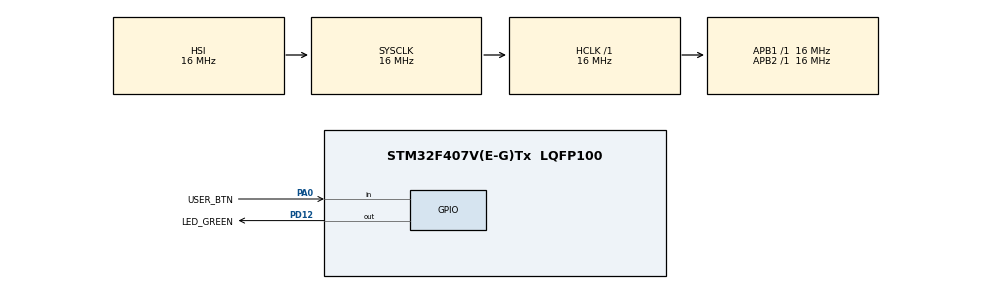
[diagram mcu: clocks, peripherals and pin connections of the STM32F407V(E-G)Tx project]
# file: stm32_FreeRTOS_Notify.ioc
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FREERTOS.Tasks01=LEDTask,25,500,StartLEDTask,Default,NULL,Dynamic,NULL,NULL;BTNTask,25,500,StartBTNTask,Default,NULL,Dynamic,NULL,NULL
FREERTOS.configUSE_NEWLIB_REENTRANT=1
Mcu.Family=STM32F4
Mcu.Name=STM32F407V(E-G)Tx
Mcu.Package=LQFP100
NVIC.PriorityGroup=NVIC_PRIORITYGROUP_4
NVIC.TIM6_DAC_IRQn=true\:15\:0\:false\:false\:true\:false\:false\:true\:true
NVIC.TimeBase=TIM6_DAC_IRQn
NVIC.TimeBaseIP=TIM6
PA0-WKUP.GPIO_Label=USER_BTN
PA0-WKUP.Signal=GPIO_Input
PD12.GPIO_Label=LED_GREEN
PD12.Signal=GPIO_Output
ProjectManager.HeapSize=0x200
ProjectManager.StackSize=0x400
ProjectManager.TargetToolchain=STM32CubeIDE
RCC.AHBFreq_Value=16000000
RCC.APB1Freq_Value=16000000
RCC.APB2Freq_Value=16000000
RCC.CortexFreq_Value=16000000
RCC.HSE_VALUE=25000000
RCC.HSI_VALUE=16000000
RCC.LSE_VALUE=32768
RCC.SYSCLKFreq_VALUE=16000000
RCC.VCOOutputFreq_Value=192000000
VP_FREERTOS_VS_CMSIS_V2.Mode=CMSIS_V2
VP_SYS_VS_tim6.Mode=TIM6
board=custom

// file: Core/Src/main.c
/* USER CODE BEGIN Header */
/**
  ******************************************************************************
  * @file           : main.c
  * @brief          : Main program body
  ******************************************************************************
  * @attention
  *
  * Copyright (c) 2022 STMicroelectronics.
  * All rights reserved.
  *
  * This software is licensed under terms that can be found in the LICENSE file
  * in the root directory of this software component.
  * If no LICENSE file comes with this software, it is provided AS-IS.
  *
  ******************************************************************************
  */
/* USER CODE END Header */
#include "main.h"
#include "cmsis_os.h"

/* Definitions for LEDTask */
osThreadId_t LEDTaskHandle;
const osThreadAttr_t LEDTask_attributes = {
  .name = "LEDTask",
  .stack_size = 500 * 4,
  .priority = (osPriority_t) osPriorityNormal1,
};
/* Definitions for BTNTask */
osThreadId_t BTNTaskHandle;
const osThreadAttr_t BTNTask_attributes = {
  .name = "BTNTask",
  .stack_size = 500 * 4,
  .priority = (osPriority_t) osPriorityNormal1,
};

void SystemClock_Config(void);
static void MX_GPIO_Init(void);
void StartLEDTask(void *argument);
void StartBTNTask(void *argument);

/* USER CODE BEGIN PFP */
void rtos_delay (uint32_t delay_in_ms);

/* USER CODE END PFP */

/* USER CODE BEGIN 0 */

void rtos_delay (uint32_t delay_in_ms)
{
	uint32_t current_tick_count = xTaskGetTickCount();
	uint32_t delay_in_ticks = (delay_in_ms * configTICK_RATE_HZ) / 1000;
	while (xTaskGetTickCount() < current_tick_count + delay_in_ticks);
}

/* USER CODE END 0 */

int main(void)
{

  /* MCU Configuration--------------------------------------------------------*/

  /* Reset of all peripherals, Initializes the Flash interface and the Systick. */
  HAL_Init();

  /* Configure the system clock */
  SystemClock_Config();

  /* Initialize all configured peripherals */
  MX_GPIO_Init();

  /* Init scheduler */
  osKernelInitialize();

  /* Create the thread(s) */
  /* creation of LEDTask */
  LEDTaskHandle = osThreadNew(StartLEDTask, NULL, &LEDTask_attributes);

  /* creation of BTNTask */
  BTNTaskHandle = osThreadNew(StartBTNTask, NULL, &BTNTask_attributes);

  /* Start scheduler */
  osKernelStart();

  /* We should never get here as control is now taken by the scheduler */
  /* Infinite loop */
  while (1)
  {

  }
}

void SystemClock_Config(void)
{
  RCC_OscInitTypeDef RCC_OscInitStruct = {0};
  RCC_ClkInitTypeDef RCC_ClkInitStruct = {0};

  /** Configure the main internal regulator output voltage
  */
  __HAL_RCC_PWR_CLK_ENABLE();
  __HAL_PWR_VOLTAGESCALING_CONFIG(PWR_REGULATOR_VOLTAGE_SCALE1);

  /** Initializes the RCC Oscillators according to the specified parameters
  * in the RCC_OscInitTypeDef structure.
  */
  RCC_OscInitStruct.OscillatorType = RCC_OSCILLATORTYPE_HSI;
  RCC_OscInitStruct.HSIState = RCC_HSI_ON;
  RCC_OscInitStruct.HSICalibrationValue = RCC_HSICALIBRATION_DEFAULT;
  RCC_OscInitStruct.PLL.PLLState = RCC_PLL_NONE;
  if (HAL_RCC_OscConfig(&RCC_OscInitStruct) != HAL_OK)
  {
    Error_Handler();
  }

  /** Initializes the CPU, AHB and APB buses clocks
  */
  RCC_ClkInitStruct.ClockType = RCC_CLOCKTYPE_HCLK|RCC_CLOCKTYPE_SYSCLK
                              |RCC_CLOCKTYPE_PCLK1|RCC_CLOCKTYPE_PCLK2;
  RCC_ClkInitStruct.SYSCLKSource = RCC_SYSCLKSOURCE_HSI;
  RCC_ClkInitStruct.AHBCLKDivider = RCC_SYSCLK_DIV1;
  RCC_ClkInitStruct.APB1CLKDivider = RCC_HCLK_DIV1;
  RCC_ClkInitStruct.APB2CLKDivider = RCC_HCLK_DIV1;

  if (HAL_RCC_ClockConfig(&RCC_ClkInitStruct, FLASH_LATENCY_0) != HAL_OK)
  {
    Error_Handler();
  }
}

static void MX_GPIO_Init(void)
{
  GPIO_InitTypeDef GPIO_InitStruct = {0};

  /* GPIO Ports Clock Enable */
  __HAL_RCC_GPIOA_CLK_ENABLE();
  __HAL_RCC_GPIOD_CLK_ENABLE();

  /*Configure GPIO pin Output Level */
  HAL_GPIO_WritePin(GPIOD, GPIO_PIN_12, GPIO_PIN_RESET);

  /*Configure GPIO pin : PA0 */
  GPIO_InitStruct.Pin = GPIO_PIN_0;
  GPIO_InitStruct.Mode = GPIO_MODE_INPUT;
  GPIO_InitStruct.Pull = GPIO_NOPULL;
  HAL_GPIO_Init(GPIOA, &GPIO_InitStruct);

  /*Configure GPIO pin : PD12 */
  GPIO_InitStruct.Pin = GPIO_PIN_12;
  GPIO_InitStruct.Mode = GPIO_MODE_OUTPUT_PP;
  GPIO_InitStruct.Pull = GPIO_NOPULL;
  GPIO_InitStruct.Speed = GPIO_SPEED_FREQ_LOW;
  HAL_GPIO_Init(GPIOD, &GPIO_InitStruct);

}

void StartLEDTask(void *argument)
{
  /* USER CODE BEGIN 5 */
	uint32_t current_noti_value = 0;
  /* Infinite loop */
  for(;;)
  {
	  //Wait until notification from another task
	  	  if (xTaskNotifyWait(0, 0, &current_noti_value, portMAX_DELAY) == pdTRUE)
	  	  {
	  		  //receive notification and toggle the LED
	  		  HAL_GPIO_TogglePin(LED_GREEN_GPIO_Port, LED_GREEN_Pin);
	  	  }
//    osDelay(1);
  }
  /* USER CODE END 5 */
}

void StartBTNTask(void *argument)
{
  /* USER CODE BEGIN StartBTNTask */
  /* Infinite loop */
  for(;;)
  {
	  if(HAL_GPIO_ReadPin(USER_BTN_GPIO_Port, USER_BTN_Pin))
	  {
		  rtos_delay(100);
		  xTaskNotify(LEDTaskHandle, 0x0, eNoAction);
	  }

//    osDelay(1);
  }
  /* USER CODE END StartBTNTask */
}

void HAL_TIM_PeriodElapsedCallback(TIM_HandleTypeDef *htim)
{
  if (htim->Instance == TIM6) {
    HAL_IncTick();
  }
}

void Error_Handler(void)
{
  __disable_irq();
  while (1)
  {
  }
}
